# ATmega32U2 register map
Vendor: Atmel; File version: 1.0
CPU: other r0p0, little endian, no MPU, no FPU, 4 interrupt priority bits
Registers are 8-bit, read-write, reset 0x0 unless marked. A register's access mark holds for its fields unless they carry their own. Offsets are from the block's base; lines under a group give offsets from that group; [hi:lo] are bit positions; {n}, {i} and the like mark numbered series; 'fields as' and 'values as' point back to an identical list; <NAME> marks a mode.

## Memory map
0x00800023 PORTB size 0x3 — I/O Port
0x00800026 PORTC size 0x3 — I/O Port
0x00800029 PORTD size 0x3 — I/O Port
0x00800035 TC0 blocks up to offset 0x3A — Timer/Counter, 8-bit
0x00800036 TC1 blocks up to offset 0x58 — Timer/Counter, 16-bit
0x0080003B EXINT blocks up to offset 0x32 — External Interrupts
0x0080003E CPU blocks up to offset 0x95 — CPU Registers
0x0080003F EEPROM size 0x4
0x00800049 PLL size 0x1 — Phase Locked Loop
0x0080004C SPI size 0x3 — Serial Peripheral Interface
0x00800050 AC blocks up to offset 0x30 — Analog Comparator
0x00800057 BOOT_LOAD size 0x1 — Bootloader
0x00800060 WDT blocks up to offset 0x3 — Watchdog Timer
0x00800063 USB_DEVICE blocks up to offset 0x99 — USB Device Registers
0x008000C8 USART1 size 0x7 — USART

## Interrupts
0 RESET (CPU) — External Pin,Power-on Reset,Brown-out Reset,Watchdog Reset,and JTAG AVR Reset. See Datasheet.
{n+1} INT{n} (CPU) (n=0..7) — External Interrupt Request {n}
9 PCINT0 (CPU) — Pin Change Interrupt Request 0
10 PCINT1 (CPU) — Pin Change Interrupt Request 1
11 USB_GEN (CPU) — USB General Interrupt Request
12 USB_COM (CPU) — USB Endpoint/Pipe Interrupt Communication Request
13 WDT (CPU) — Watchdog Time-out Interrupt
14 TIMER1_CAPT (CPU) — Timer/Counter2 Capture Event
15 TIMER1_COMPA (CPU) — Timer/Counter2 Compare Match B
16 TIMER1_COMPB (CPU) — Timer/Counter2 Compare Match B
17 TIMER1_COMPC (CPU) — Timer/Counter2 Compare Match C
18 TIMER1_OVF (CPU) — Timer/Counter1 Overflow
19 TIMER0_COMPA (CPU) — Timer/Counter0 Compare Match A
20 TIMER0_COMPB (CPU) — Timer/Counter0 Compare Match B
21 TIMER0_OVF (CPU) — Timer/Counter0 Overflow
22 SPI_STC (CPU) — SPI Serial Transfer Complete
23 USART1_RX (CPU) — USART1, Rx Complete
24 USART1_UDRE (CPU) — USART1 Data register Empty
25 USART1_TX (CPU) — USART1, Tx Complete
26 ANALOG_COMP (CPU) — Analog Comparator
27 EE_READY (CPU) — EEPROM Ready
28 SPM_READY (CPU) — Store Program Memory Read

## AC — Analog Comparator
Base 0x00800050
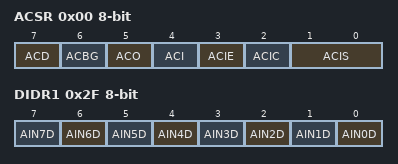
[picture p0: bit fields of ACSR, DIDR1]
0x00 ACSR — Analog Comparator Control And Status Register (read-only for debugger)
  [7] ACD — Analog Comparator Disable
  [6] ACBG — Analog Comparator Bandgap Select
  [5] ACO — Analog Compare Output
  [4] ACI — Analog Comparator Interrupt Flag
  [3] ACIE — Analog Comparator Interrupt Enable
  [2] ACIC — Analog Comparator Input Capture Enable
  [1:0] ACIS — Analog Comparator Interrupt Mode Select bits
    0=INTERRUPT_ON_TOGGLE; 2=INTERRUPT_ON_FALLING_EDGE; 3=INTERRUPT_ON_RISING_EDGE
0x2D ACMUX — Analog Comparator Input Multiplexer
  [2:0] CMUX — Analog Comparator Selection Bits
    {v}=AIN{v+1} (v=0..5)
0x2F DIDR1
  [n] AIN{n}D (n=0..7) — AIN{n} Digital Input Disable

## BOOT_LOAD — Bootloader
Base 0x00800057
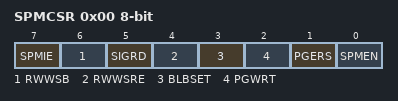
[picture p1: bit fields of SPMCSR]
0x00 SPMCSR — Store Program Memory Control Register
  [7] SPMIE — SPM Interrupt Enable
  [6] RWWSB — Read While Write Section Busy
  [5] SIGRD — Signature Row Read
  [4] RWWSRE — Read While Write section read enable
  [3] BLBSET — Boot Lock Bit Set
  [2] PGWRT — Page Write
  [1] PGERS — Page Erase
  [0] SPMEN — Store Program Memory Enable

## CPU — CPU Registers
Base 0x0080003E
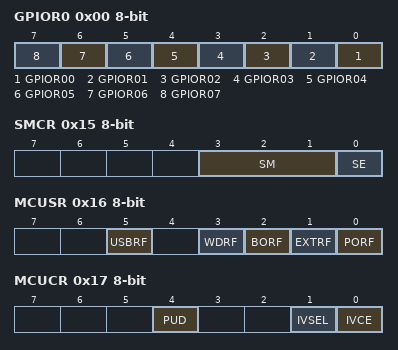
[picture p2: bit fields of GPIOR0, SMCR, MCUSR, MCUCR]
0x00 GPIOR0 — General Purpose IO Register 0
  [n] GPIOR{n:02} (n=0..7) — General Purpose IO Register 0 bit {n}
0x0C GPIOR1 — General Purpose IO Register 1
  [7:0] GPIOR — General Purpose IO Register 1 bis
0x0D GPIOR2 — General Purpose IO Register 2
  [7:0] GPIOR — General Purpose IO Register 2 bis
0x13 DWDR — debugWire communication register (write-only for debugger)
0x15 SMCR — Sleep Mode Control Register
  [3:1] SM — Sleep Mode Select bits
    0=IDLE; 2=PDOWN (Power Down); 3=PSAVE (Power Save); 6=STDBY (Standby); 7=ESTDBY (Extended Standby)
  [0] SE — Sleep Enable
0x16 MCUSR — MCU Status Register
  [5] USBRF — USB reset flag
  [3] WDRF — Watchdog Reset Flag
  [2] BORF — Brown-out Reset Flag
  [1] EXTRF — External Reset Flag
  [0] PORF — Power-on reset flag
0x17 MCUCR — MCU Control Register
  [4] PUD — Pull-up disable
  [1] IVSEL — Interrupt Vector Select
  [0] IVCE — Interrupt Vector Change Enable
0x1E EIND — Extended Indirect Register
0x1F SP 16-bit (reset mask 0xFF) — Stack Pointer
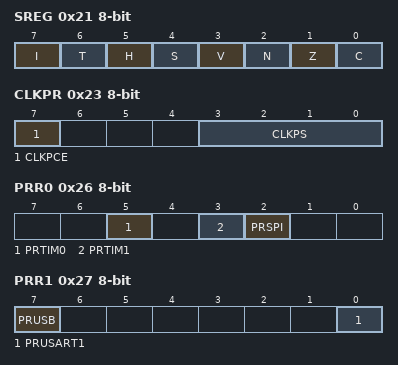
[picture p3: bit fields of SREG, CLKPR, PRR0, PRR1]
0x21 SREG — Status Register
  [7] I — Global Interrupt Enable
  [6] T — Bit Copy Storage
  [5] H — Half Carry Flag
  [4] S — Sign Bit
  [3] V — Two's Complement Overflow Flag
  [2] N — Negative Flag
  [1] Z — Zero Flag
  [0] C — Carry Flag
0x23 CLKPR
  [7] CLKPCE, [3:0] CLKPS
0x26 PRR0 — Power Reduction Register0
  [5] PRTIM0 — Power Reduction Timer/Counter0
  [3] PRTIM1 — Power Reduction Timer/Counter1
  [2] PRSPI — Power Reduction Serial Peripheral Interface
0x27 PRR1 — Power Reduction Register1
  [7] PRUSB — Power Reduction USB
  [0] PRUSART1 — Power Reduction USART1
0x28 OSCCAL — Oscillator Calibration Value (read-only for debugger)
  [7:0] OSCCAL — Oscillator Calibration
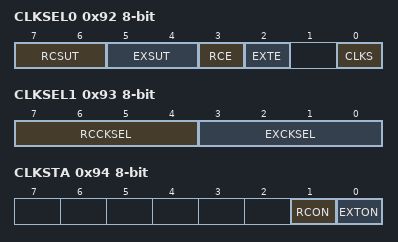
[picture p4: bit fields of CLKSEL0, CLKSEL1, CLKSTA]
0x92 CLKSEL0
  [7:6] RCSUT, [5:4] EXSUT, [3] RCE, [2] EXTE, [0] CLKS
0x93 CLKSEL1
  [7:4] RCCKSEL, [3:0] EXCKSEL
0x94 CLKSTA
  [1] RCON, [0] EXTON
